# LargeDummyDevice register map
File version: 1.0
Registers are 32-bit, read-write, no defined reset value unless marked. A register's access mark holds for its fields unless they carry their own. Offsets are from the block's base; [hi:lo] are bit positions.

## PERIPHERAL_54
Base 0x40035000
0x04 REG_1 — Register 1
  [31] FIELD_4, [32:29] FIELD_2, [28] FIELD_13, [26:24] FIELD_16, [25:21] FIELD_7, [24:21] FIELD_17, [19] FIELD_12, [20:17] FIELD_8, [16] FIELD_1, [18:16] FIELD_3, [17:16] FIELD_11, [13:12] FIELD_10, [15:11] FIELD_6, [6:4] FIELD_14, [8:4] FIELD_15, [6:3] FIELD_5, [3] FIELD_9
0x08 REG_2 — Register 2
  [33:31] FIELD_2, [34:30] FIELD_9, [31:30] FIELD_13, [29] FIELD_4, [27] FIELD_15, [27:26] FIELD_8, [26:25] FIELD_16, [24] FIELD_17, [26:22] FIELD_5, [23:22] FIELD_10, [24:20] FIELD_11, [20:19] FIELD_6, [16] FIELD_14, [12:9] FIELD_7, [7:5] FIELD_3, [8:4] FIELD_1, [4:3] FIELD_12
0x0C REG_3 — Register 3
  [29:28] FIELD_1
0x10 REG_4 — Register 4
  [35:31] FIELD_1, [10] FIELD_4, [10] FIELD_5, [10:9] FIELD_2, [4:2] FIELD_3
0x14 REG_5 — Register 5
  [31:30] FIELD_14, [30:29] FIELD_16, [31:28] FIELD_6, [31:28] FIELD_20, [28] FIELD_26, [29:27] FIELD_5, [24] FIELD_4, [28:24] FIELD_23, [23] FIELD_15, [23] FIELD_21, [24:23] FIELD_28, [25:22] FIELD_25, [23:21] FIELD_1, [22:21] FIELD_7, [21] FIELD_8, [17:14] FIELD_9, [17:13] FIELD_24, [14:11] FIELD_27, [12:9] FIELD_19, [12:8] FIELD_18, [9:6] FIELD_11, [8:5] FIELD_2, [6:4] FIELD_17, [6:4] FIELD_22, [3:2] FIELD_10, [5:2] FIELD_12, [4:1] FIELD_3, [4:1] FIELD_13
0x18 REG_6 — Register 6
  [34:31] FIELD_9, [34:30] FIELD_3, [32:29] FIELD_12, [29] FIELD_25, [31:27] FIELD_13, [29:27] FIELD_20, [23] FIELD_5, [22] FIELD_8, [22:21] FIELD_23, [21:20] FIELD_4, [21:20] FIELD_17, [22:20] FIELD_19, [23:19] FIELD_18, [22:19] FIELD_27, [19:18] FIELD_26, [21:17] FIELD_22, [16] FIELD_14, [17:15] FIELD_10, [14] FIELD_7, [10] FIELD_21, [6] FIELD_16, [9:5] FIELD_1, [4] FIELD_15, [6:4] FIELD_24, [6:2] FIELD_6, [4:0] FIELD_2, [0] FIELD_11
0x1C REG_7 — Register 7
  [34:31] FIELD_2, [31:27] FIELD_4, [16:13] FIELD_3, [10:9] FIELD_1, [7] FIELD_5
0x20 REG_8 — Register 8
  [32:30] FIELD_1, [31:27] FIELD_17, [27:24] FIELD_2, [22:19] FIELD_18, [21:17] FIELD_4, [18:17] FIELD_7, [20:16] FIELD_10, [19:15] FIELD_14, [19:15] FIELD_15, [14:12] FIELD_5, [15:12] FIELD_6, [16:12] FIELD_13, [12:11] FIELD_12, [11:10] FIELD_11, [13:9] FIELD_16, [7:4] FIELD_8, [4:1] FIELD_3, [3:1] FIELD_9
0x24 REG_9 — Register 9
  [29:25] FIELD_1, [5:4] FIELD_3, [5:1] FIELD_2
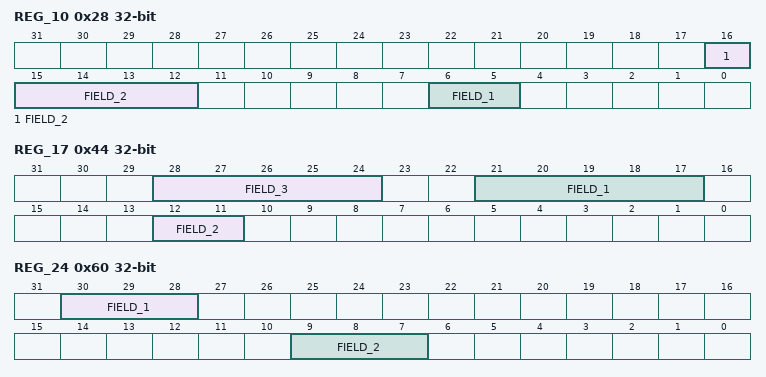
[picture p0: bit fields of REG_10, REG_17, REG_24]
0x28 REG_10 — Register 10
  [16:12] FIELD_2, [6:5] FIELD_1
0x2C REG_11 — Register 11
  [28:26] FIELD_9, [22] FIELD_6, [23:19] FIELD_1, [19:16] FIELD_2, [18:15] FIELD_8, [13:11] FIELD_3, [9:5] FIELD_7, [7:4] FIELD_5, [2:0] FIELD_4
0x30 REG_12 — Register 12
  [32:29] FIELD_4, [33:29] FIELD_6, [27:26] FIELD_7, [25] FIELD_8, [21:20] FIELD_2, [19:15] FIELD_5, [10] FIELD_1, [11:8] FIELD_9, [10:6] FIELD_3
0x34 REG_13 — Register 13
  [34:31] FIELD_4, [20:17] FIELD_1, [15] FIELD_3, [15:11] FIELD_2, [8:4] FIELD_5, [4:0] FIELD_6
0x38 REG_14 — Register 14
  [35:31] FIELD_8, [31] FIELD_17, [34:30] FIELD_20, [31:29] FIELD_27, [32:29] FIELD_28, [31:28] FIELD_2, [30:26] FIELD_9, [27:26] FIELD_18, [28:26] FIELD_30, [24] FIELD_21, [27:23] FIELD_19, [26:22] FIELD_1, [22:18] FIELD_4, [19:18] FIELD_13, [21:17] FIELD_16, [17] FIELD_24, [15] FIELD_3, [16:15] FIELD_11, [16:15] FIELD_23, [18:14] FIELD_14, [15:14] FIELD_25, [18:14] FIELD_29, [11:10] FIELD_15, [11:8] FIELD_7, [8:6] FIELD_22, [8:5] FIELD_5, [7:5] FIELD_10, [4:2] FIELD_26, [1] FIELD_12, [4:0] FIELD_6
0x3C REG_15 — Register 15
  [31] FIELD_26, [31:30] FIELD_1, [33:29] FIELD_27, [29:26] FIELD_11, [29:26] FIELD_22, [27:25] FIELD_28, [27:24] FIELD_8, [24:23] FIELD_24, [21] FIELD_10, [23:20] FIELD_23, [22:19] FIELD_16, [17] FIELD_25, [18:16] FIELD_14, [16] FIELD_21, [19:16] FIELD_29, [19:15] FIELD_12, [17:14] FIELD_7, [15:13] FIELD_2, [13:11] FIELD_18, [15:11] FIELD_31, [14:10] FIELD_30, [12:9] FIELD_9, [11:7] FIELD_19, [7:6] FIELD_4, [10:6] FIELD_6, [7:6] FIELD_20, [5] FIELD_3, [6:3] FIELD_13, [4:2] FIELD_5, [2:1] FIELD_17, [3:0] FIELD_15
0x40 REG_16 — Register 16
  [33:31] FIELD_26, [29] FIELD_24, [30:28] FIELD_17, [31:27] FIELD_31, [27:25] FIELD_29, [26:24] FIELD_28, [28:24] FIELD_30, [25:23] FIELD_16, [26:23] FIELD_22, [20] FIELD_1, [21:19] FIELD_18, [22:19] FIELD_19, [20:18] FIELD_5, [19:17] FIELD_21, [17] FIELD_25, [19:16] FIELD_32, [19:15] FIELD_2, [19:15] FIELD_14, [17:15] FIELD_20, [16:14] FIELD_23, [16:13] FIELD_10, [17:13] FIELD_13, [11] FIELD_3, [8] FIELD_6, [10:8] FIELD_12, [9:7] FIELD_4, [11:7] FIELD_8, [10:7] FIELD_11, [10:6] FIELD_15, [5] FIELD_7, [4:2] FIELD_9, [4:1] FIELD_27
0x44 REG_17 — Register 17
  [28:24] FIELD_3, [21:17] FIELD_1, [12:11] FIELD_2
0x48 REG_18 — Register 18
  [29:25] FIELD_1, [13] FIELD_4, [14:10] FIELD_3, [10:9] FIELD_2, [10:8] FIELD_5
0x4C REG_19 — Register 19
  [34:30] FIELD_9, [32:28] FIELD_7, [28] FIELD_12, [32:28] FIELD_15, [27:26] FIELD_13, [21:17] FIELD_4, [20:17] FIELD_5, [17:16] FIELD_3, [17:15] FIELD_6, [16:13] FIELD_14, [15:12] FIELD_10, [11:7] FIELD_16, [4] FIELD_11, [7:3] FIELD_1, [6:2] FIELD_2, [4:2] FIELD_8, [2] FIELD_17
0x50 REG_20 — Register 20
  [31] FIELD_3, [32:30] FIELD_10, [28:25] FIELD_2, [23:22] FIELD_1, [24:21] FIELD_6, [19] FIELD_9, [18:17] FIELD_8, [10:8] FIELD_5, [8:4] FIELD_7, [2] FIELD_4
0x54 REG_21 — Register 21
  [34:31] FIELD_1, [33:30] FIELD_3, [30:27] FIELD_5, [29:25] FIELD_6, [24:23] FIELD_2, [24:21] FIELD_7, [12:10] FIELD_4
0x58 REG_22 — Register 22
  [31] FIELD_3, [32:30] FIELD_6, [29] FIELD_9, [18:14] FIELD_5, [12:10] FIELD_1, [14:10] FIELD_10, [6] FIELD_4, [6] FIELD_7, [7:3] FIELD_8, [4:3] FIELD_12, [5:2] FIELD_11, [5:1] FIELD_2
0x5C REG_23 — Register 23
  [33:31] FIELD_6, [34:31] FIELD_10, [30:29] FIELD_3, [30:28] FIELD_13, [28] FIELD_19, [29:25] FIELD_4, [26:25] FIELD_14, [24:23] FIELD_1, [24:23] FIELD_12, [22] FIELD_24, [21:20] FIELD_5, [23:20] FIELD_18, [20] FIELD_26, [18:17] FIELD_9, [18:16] FIELD_2, [17:16] FIELD_20, [16] FIELD_21, [17:14] FIELD_8, [14:13] FIELD_17, [12:9] FIELD_7, [11:9] FIELD_23, [8:4] FIELD_11, [7:4] FIELD_15, [5:3] FIELD_27, [6:2] FIELD_22, [4:2] FIELD_25, [1] FIELD_16
0x60 REG_24 — Register 24
  [30:28] FIELD_1, [9:7] FIELD_2
0x64 REG_25 — Register 25
  [33:31] FIELD_7, [31:30] FIELD_4, [28:26] FIELD_9, [27:23] FIELD_5, [24:21] FIELD_1, [25:21] FIELD_8, [22:21] FIELD_11, [16:12] FIELD_3, [14:10] FIELD_13, [9] FIELD_14, [10:7] FIELD_2, [8:7] FIELD_10, [4:2] FIELD_6, [1] FIELD_12
0x68 REG_26 — Register 26
  [33:31] FIELD_6, [30:27] FIELD_2, [23] FIELD_3, [26:23] FIELD_8, [20] FIELD_4, [18:17] FIELD_10, [14:11] FIELD_12, [1] FIELD_1, [5:1] FIELD_5, [1] FIELD_7, [5:1] FIELD_9, [1:0] FIELD_11
0x6C REG_27 — Register 27
  [32:31] FIELD_1, [34:30] FIELD_15, [30:29] FIELD_18, [30:28] FIELD_19, [29:26] FIELD_12, [26:24] FIELD_17, [19:18] FIELD_6, [18:17] FIELD_11, [20:16] FIELD_3, [18:16] FIELD_9, [14:13] FIELD_5, [12] FIELD_8, [13:12] FIELD_14, [13:11] FIELD_7, [13:10] FIELD_16, [10:9] FIELD_4, [12:9] FIELD_13, [3] FIELD_10, [4:3] FIELD_20, [2:1] FIELD_2
0x70 REG_28 — Register 28
  [30:29] FIELD_7, [30:28] FIELD_20, [27] FIELD_17, [27] FIELD_24, [30:26] FIELD_28, [28:25] FIELD_16, [26:24] FIELD_2, [25:24] FIELD_14, [23:21] FIELD_9, [24:21] FIELD_15, [21] FIELD_22, [21] FIELD_29, [19] FIELD_10, [21:17] FIELD_13, [20:16] FIELD_25, [18:15] FIELD_12, [14:13] FIELD_3, [15:13] FIELD_6, [13] FIELD_19, [14:13] FIELD_30, [14:11] FIELD_4, [10:9] FIELD_18, [10:8] FIELD_26, [8:7] FIELD_5, [8:5] FIELD_8, [3] FIELD_23, [4:3] FIELD_27, [5:1] FIELD_1, [1] FIELD_11, [2:0] FIELD_21
0x74 REG_29 — Register 29
  [33:30] FIELD_1, [27] FIELD_2, [29:27] FIELD_19, [29:26] FIELD_11, [30:26] FIELD_14, [23:22] FIELD_10, [25:22] FIELD_17, [25:22] FIELD_18, [22:20] FIELD_3, [23:19] FIELD_8, [19:18] FIELD_4, [17] FIELD_16, [19:16] FIELD_5, [15:14] FIELD_15, [16:13] FIELD_9, [16:12] FIELD_7, [16:12] FIELD_12, [15:11] FIELD_6, [4] FIELD_13
0x78 REG_30 — Register 30
  [18:17] FIELD_1
0x7C REG_31 — Register 31
  [31:30] FIELD_1
0x80 REG_32 — Register 32
  [32:31] FIELD_20, [32:30] FIELD_1, [33:30] FIELD_12, [33:29] FIELD_28, [33:29] FIELD_29, [29:28] FIELD_10, [28] FIELD_15, [30:28] FIELD_26, [27:26] FIELD_22, [30:26] FIELD_24, [28:25] FIELD_2, [27:23] FIELD_17, [26:23] FIELD_21, [25:21] FIELD_9, [19] FIELD_6, [19:18] FIELD_16, [18:16] FIELD_7, [20:16] FIELD_13, [16:15] FIELD_3, [14:13] FIELD_23, [13] FIELD_27, [16:12] FIELD_11, [13:9] FIELD_5, [13:9] FIELD_25, [12:8] FIELD_8, [6] FIELD_19, [8:4] FIELD_18, [2] FIELD_4, [4:2] FIELD_14
0x84 REG_33 — Register 33
  [33:31] FIELD_3, [32:31] FIELD_9, [31:28] FIELD_1, [29:28] FIELD_20, [28:25] FIELD_5, [26:24] FIELD_13, [24:23] FIELD_8, [26:23] FIELD_17, [22:21] FIELD_2, [22:20] FIELD_21, [23:19] FIELD_6, [20:19] FIELD_18, [14] FIELD_12, [16:14] FIELD_15, [11] FIELD_14, [12:9] FIELD_7, [11:9] FIELD_16, [9:7] FIELD_11, [9:5] FIELD_4, [7:4] FIELD_19, [2] FIELD_10, [2:1] FIELD_22
0x88 REG_34 — Register 34
  [33:29] FIELD_3, [31:29] FIELD_21, [31:28] FIELD_5, [29:27] FIELD_13, [31:27] FIELD_15, [31:27] FIELD_26, [27:26] FIELD_2, [27:26] FIELD_20, [26:25] FIELD_7, [25] FIELD_25, [26:24] FIELD_4, [22] FIELD_12, [22:20] FIELD_8, [18:17] FIELD_22, [16:14] FIELD_16, [14:12] FIELD_10, [13:11] FIELD_9, [11] FIELD_19, [13:10] FIELD_14, [11:10] FIELD_24, [7] FIELD_6, [10:7] FIELD_28, [10:6] FIELD_11, [7:3] FIELD_1, [7:3] FIELD_18, [3] FIELD_27, [5:2] FIELD_23, [4:1] FIELD_29, [2:0] FIELD_17
0x8C REG_35 — Register 35
  [32:30] FIELD_27, [28] FIELD_1, [31:28] FIELD_17, [26] FIELD_5, [25] FIELD_24, [25:24] FIELD_4, [28:24] FIELD_19, [26:23] FIELD_22, [24:23] FIELD_25, [26:22] FIELD_11, [22:19] FIELD_13, [20:18] FIELD_9, [22:18] FIELD_15, [19:18] FIELD_20, [17:15] FIELD_6, [16:13] FIELD_8, [14:11] FIELD_21, [14:10] FIELD_23, [9:8] FIELD_14, [8:7] FIELD_2, [10:7] FIELD_26, [10:6] FIELD_7, [8:5] FIELD_3, [9:5] FIELD_12, [6:5] FIELD_16, [6:4] FIELD_10, [1:0] FIELD_18
0x90 REG_36 — Register 36
  [28:26] FIELD_3, [18:16] FIELD_1, [17:14] FIELD_5, [17:14] FIELD_9, [16:12] FIELD_8, [12:11] FIELD_4, [6] FIELD_6, [10:6] FIELD_7, [5:3] FIELD_2
0x94 REG_37 — Register 37
  [32:31] FIELD_1
0x98 REG_38 — Register 38
  [29:28] FIELD_5, [28] FIELD_8, [27:23] FIELD_11, [22:21] FIELD_1, [22:21] FIELD_4, [23:21] FIELD_7, [21:20] FIELD_3, [21:20] FIELD_10, [21:18] FIELD_9, [13:10] FIELD_6, [9] FIELD_2
0x9C REG_39 — Register 39
  [30] FIELD_7, [33:30] FIELD_8, [34:30] FIELD_11, [24] FIELD_5, [27:24] FIELD_15, [23:22] FIELD_4, [21:18] FIELD_6, [19:16] FIELD_1, [19:16] FIELD_13, [16:15] FIELD_2, [18:15] FIELD_9, [14] FIELD_16, [14:13] FIELD_12, [14:12] FIELD_3, [16:12] FIELD_10, [8:7] FIELD_14
0xA0 REG_40 — Register 40
  [30:29] FIELD_7, [32:29] FIELD_9, [28] FIELD_12, [28] FIELD_14, [29:25] FIELD_1, [24:23] FIELD_8, [20] FIELD_11, [17] FIELD_6, [18:14] FIELD_10, [13] FIELD_13, [9:7] FIELD_2, [8:7] FIELD_5, [9:5] FIELD_4, [1:0] FIELD_3
0xA4 REG_41 — Register 41
  [33:30] FIELD_14, [28:24] FIELD_9, [23:22] FIELD_2, [22] FIELD_3, [22:19] FIELD_4, [18] FIELD_6, [16] FIELD_15, [17:14] FIELD_17, [13:12] FIELD_5, [15:11] FIELD_7, [15:11] FIELD_13, [14:10] FIELD_12, [13:9] FIELD_8, [6:5] FIELD_11, [5] FIELD_16, [6:3] FIELD_1, [4:3] FIELD_10, [2:1] FIELD_18
